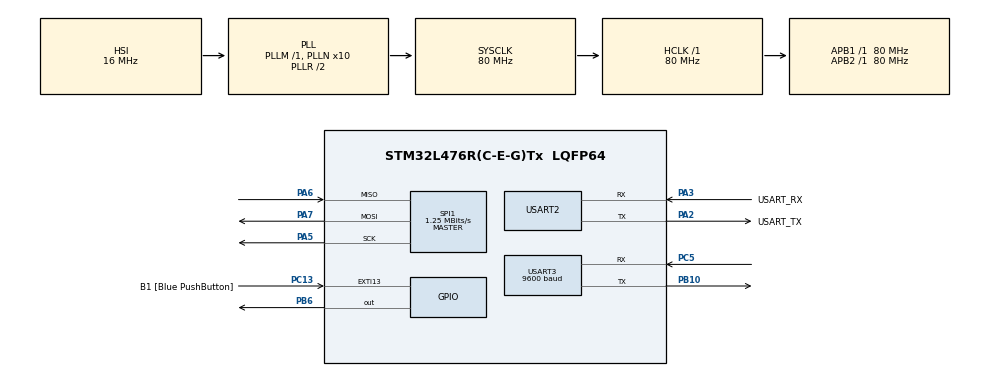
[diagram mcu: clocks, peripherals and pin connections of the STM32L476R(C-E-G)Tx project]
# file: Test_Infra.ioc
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Mcu.Family=STM32L4
Mcu.Name=STM32L476R(C-E-G)Tx
Mcu.Package=LQFP64
NVIC.PriorityGroup=NVIC_PRIORITYGROUP_4
PA13\ (JTMS-SWDIO).GPIO_Label=TMS
PA13\ (JTMS-SWDIO).Mode=Serial_Wire
PA13\ (JTMS-SWDIO).Signal=SYS_JTMS-SWDIO
PA14\ (JTCK-SWCLK).GPIO_Label=TCK
PA14\ (JTCK-SWCLK).Mode=Serial_Wire
PA14\ (JTCK-SWCLK).Signal=SYS_JTCK-SWCLK
PA2.GPIO_Label=USART_TX
PA2.GPIO_Mode=GPIO_MODE_AF_PP
PA2.GPIO_PuPd=GPIO_NOPULL
PA2.GPIO_Speed=GPIO_SPEED_FREQ_VERY_HIGH
PA2.Mode=Asynchronous
PA2.Signal=USART2_TX
PA3.GPIO_Label=USART_RX
PA3.GPIO_Mode=GPIO_MODE_AF_PP
PA3.GPIO_PuPd=GPIO_NOPULL
PA3.GPIO_Speed=GPIO_SPEED_FREQ_VERY_HIGH
PA3.Mode=Asynchronous
PA3.Signal=USART2_RX
PA5.Mode=Full_Duplex_Master
PA5.Signal=SPI1_SCK
PA6.Mode=Full_Duplex_Master
PA6.Signal=SPI1_MISO
PA7.Mode=Full_Duplex_Master
PA7.Signal=SPI1_MOSI
PB10.Mode=Asynchronous
PB10.Signal=USART3_TX
PB3\ (JTDO-TRACESWO).GPIO_Label=SWO
PB3\ (JTDO-TRACESWO).Signal=SYS_JTDO-SWO
PB6.GPIO_ModeDefaultOutputPP=GPIO_MODE_OUTPUT_PP
PB6.GPIO_Speed=GPIO_SPEED_FREQ_HIGH
PB6.PinState=GPIO_PIN_SET
PB6.Signal=GPIO_Output
PC13.GPIO_Label=B1 [Blue PushButton]
PC13.GPIO_ModeDefaultEXTI=GPIO_MODE_IT_FALLING
PC13.GPIO_PuPd=GPIO_NOPULL
PC13.Signal=GPXTI13
PC14-OSC32_IN\ (PC14).Mode=LSE-External-Oscillator
PC14-OSC32_IN\ (PC14).Signal=RCC_OSC32_IN
PC15-OSC32_OUT\ (PC15).Mode=LSE-External-Oscillator
PC15-OSC32_OUT\ (PC15).Signal=RCC_OSC32_OUT
PC5.Mode=Asynchronous
PC5.Signal=USART3_RX
PH0-OSC_IN\ (PH0).Signal=RCC_OSC_IN
PH1-OSC_OUT\ (PH1).Signal=RCC_OSC_OUT
ProjectManager.HeapSize=0x200
ProjectManager.StackSize=0x400
ProjectManager.TargetToolchain=STM32CubeIDE
RCC.ADCFreq_Value=64000000
RCC.AHBFreq_Value=80000000
RCC.APB1Freq_Value=80000000
RCC.APB1TimFreq_Value=80000000
RCC.APB2Freq_Value=80000000
RCC.APB2TimFreq_Value=80000000
RCC.CortexFreq_Value=80000000
RCC.HCLKFreq_Value=80000000
RCC.HSE_VALUE=8000000
RCC.HSI_VALUE=16000000
RCC.MSI_VALUE=4000000
RCC.PLLN=10
RCC.PLLSourceVirtual=RCC_PLLSOURCE_HSI
RCC.PREFETCH_ENABLE=1
RCC.SYSCLKFreq_VALUE=80000000
RCC.SYSCLKSource=RCC_SYSCLKSOURCE_PLLCLK
RCC.USBFreq_Value=64000000
RCC.VCOOutputFreq_Value=160000000
SPI1.BaudRatePrescaler=SPI_BAUDRATEPRESCALER_64
SPI1.CalculateBaudRate=1.25 MBits/s
SPI1.DataSize=SPI_DATASIZE_12BIT
SPI1.Direction=SPI_DIRECTION_2LINES
SPI1.Mode=SPI_MODE_MASTER
SPI1.NSSPMode=SPI_NSS_PULSE_DISABLE
SPI1.VirtualType=VM_MASTER
USART2.VirtualMode-Asynchronous=VM_ASYNC
USART3.BaudRate=9600
USART3.VirtualMode-Asynchronous=VM_ASYNC
board=NUCLEO-L476RG

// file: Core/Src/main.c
/* USER CODE BEGIN Header */
/**
  ******************************************************************************
  * @file           : main.c
  * @brief          : Main program body
  ******************************************************************************
  * @attention
  *
  * Copyright (c) 2026 STMicroelectronics.
  * All rights reserved.
  *
  * This software is licensed under terms that can be found in the LICENSE file
  * in the root directory of this software component.
  * If no LICENSE file comes with this software, it is provided AS-IS.
  *
  ******************************************************************************
  */
/* USER CODE END Header */
#include "main.h"
#include "spi.h"
#include "usart.h"
#include "gpio.h"

/* USER CODE BEGIN Includes */
#include <stdio.h>
#include "TRSensors.h"

/* USER CODE END Includes */

void SystemClock_Config(void);

/* USER CODE BEGIN 0 */

extern UART_HandleTypeDef huart3;
int _write(int file, char *ptr, int len)
{
    HAL_UART_Transmit(&huart3,(uint8_t*)ptr,len,HAL_MAX_DELAY);
    return len;
}
uint16_t mis_sensores[NUM_SENSORS];

/* USER CODE END 0 */

int main(void)
{

  /* MCU Configuration--------------------------------------------------------*/

  /* Reset of all peripherals, Initializes the Flash interface and the Systick. */
  HAL_Init();

  /* Configure the system clock */
  SystemClock_Config();

  /* Initialize all configured peripherals */
  MX_GPIO_Init();
  MX_USART2_UART_Init();
  MX_SPI1_Init();
  MX_USART3_UART_Init();

  /* Infinite loop */
  while (1)
  {

    /* USER CODE BEGIN 3 */
	  TR_Update_Sensors(mis_sensores);

	  	  printf("IR: %4d %4d %4d %4d %4d \r\n",
	  			 mis_sensores[0], mis_sensores[1], mis_sensores[2],
	  			 mis_sensores[3], mis_sensores[4]);

	  	  HAL_Delay(50);
  }
  /* USER CODE END 3 */
}

void SystemClock_Config(void)
{
  RCC_OscInitTypeDef RCC_OscInitStruct = {0};
  RCC_ClkInitTypeDef RCC_ClkInitStruct = {0};

  /** Configure the main internal regulator output voltage
  */
  if (HAL_PWREx_ControlVoltageScaling(PWR_REGULATOR_VOLTAGE_SCALE1) != HAL_OK)
  {
    Error_Handler();
  }

  /** Initializes the RCC Oscillators according to the specified parameters
  * in the RCC_OscInitTypeDef structure.
  */
  RCC_OscInitStruct.OscillatorType = RCC_OSCILLATORTYPE_HSI;
  RCC_OscInitStruct.HSIState = RCC_HSI_ON;
  RCC_OscInitStruct.HSICalibrationValue = RCC_HSICALIBRATION_DEFAULT;
  RCC_OscInitStruct.PLL.PLLState = RCC_PLL_ON;
  RCC_OscInitStruct.PLL.PLLSource = RCC_PLLSOURCE_HSI;
  RCC_OscInitStruct.PLL.PLLM = 1;
  RCC_OscInitStruct.PLL.PLLN = 10;
  RCC_OscInitStruct.PLL.PLLP = RCC_PLLP_DIV7;
  RCC_OscInitStruct.PLL.PLLQ = RCC_PLLQ_DIV2;
  RCC_OscInitStruct.PLL.PLLR = RCC_PLLR_DIV2;
  if (HAL_RCC_OscConfig(&RCC_OscInitStruct) != HAL_OK)
  {
    Error_Handler();
  }

  /** Initializes the CPU, AHB and APB buses clocks
  */
  RCC_ClkInitStruct.ClockType = RCC_CLOCKTYPE_HCLK|RCC_CLOCKTYPE_SYSCLK
                              |RCC_CLOCKTYPE_PCLK1|RCC_CLOCKTYPE_PCLK2;
  RCC_ClkInitStruct.SYSCLKSource = RCC_SYSCLKSOURCE_PLLCLK;
  RCC_ClkInitStruct.AHBCLKDivider = RCC_SYSCLK_DIV1;
  RCC_ClkInitStruct.APB1CLKDivider = RCC_HCLK_DIV1;
  RCC_ClkInitStruct.APB2CLKDivider = RCC_HCLK_DIV1;

  if (HAL_RCC_ClockConfig(&RCC_ClkInitStruct, FLASH_LATENCY_4) != HAL_OK)
  {
    Error_Handler();
  }
}

void Error_Handler(void)
{
  __disable_irq();
  while (1)
  {
  }
}
